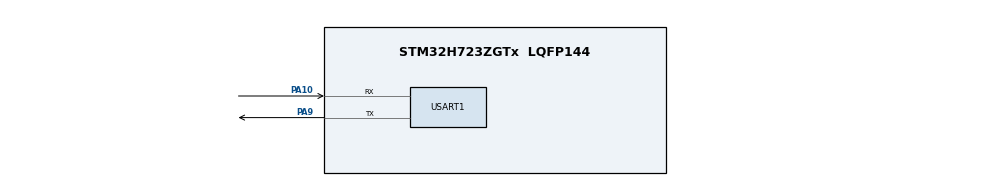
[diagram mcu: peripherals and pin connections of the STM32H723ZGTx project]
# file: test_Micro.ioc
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CORTEX_M7.default_mode_Activation=1
Dma.Request0=USART1_RX
Dma.Request1=USART1_TX
Dma.USART1_RX.0.Direction=DMA_PERIPH_TO_MEMORY
Dma.USART1_RX.0.EventEnable=DISABLE
Dma.USART1_RX.0.FIFOMode=DMA_FIFOMODE_DISABLE
Dma.USART1_RX.0.Instance=DMA1_Stream0
Dma.USART1_RX.0.MemDataAlignment=DMA_MDATAALIGN_BYTE
Dma.USART1_RX.0.MemInc=DMA_MINC_ENABLE
Dma.USART1_RX.0.Mode=DMA_CIRCULAR
Dma.USART1_RX.0.PeriphDataAlignment=DMA_PDATAALIGN_BYTE
Dma.USART1_RX.0.PeriphInc=DMA_PINC_DISABLE
Dma.USART1_RX.0.Polarity=HAL_DMAMUX_REQ_GEN_RISING
Dma.USART1_RX.0.Priority=DMA_PRIORITY_MEDIUM
Dma.USART1_RX.0.RequestNumber=1
Dma.USART1_RX.0.SignalID=NONE
Dma.USART1_RX.0.SyncEnable=DISABLE
Dma.USART1_RX.0.SyncPolarity=HAL_DMAMUX_SYNC_NO_EVENT
Dma.USART1_RX.0.SyncRequestNumber=1
Dma.USART1_RX.0.SyncSignalID=NONE
Dma.USART1_TX.1.Direction=DMA_MEMORY_TO_PERIPH
Dma.USART1_TX.1.EventEnable=DISABLE
Dma.USART1_TX.1.FIFOMode=DMA_FIFOMODE_DISABLE
Dma.USART1_TX.1.Instance=DMA1_Stream1
Dma.USART1_TX.1.MemDataAlignment=DMA_MDATAALIGN_BYTE
Dma.USART1_TX.1.MemInc=DMA_MINC_ENABLE
Dma.USART1_TX.1.Mode=DMA_NORMAL
Dma.USART1_TX.1.PeriphDataAlignment=DMA_PDATAALIGN_BYTE
Dma.USART1_TX.1.PeriphInc=DMA_PINC_DISABLE
Dma.USART1_TX.1.Polarity=HAL_DMAMUX_REQ_GEN_RISING
Dma.USART1_TX.1.Priority=DMA_PRIORITY_MEDIUM
Dma.USART1_TX.1.RequestNumber=1
Dma.USART1_TX.1.SignalID=NONE
Dma.USART1_TX.1.SyncEnable=DISABLE
Dma.USART1_TX.1.SyncPolarity=HAL_DMAMUX_SYNC_NO_EVENT
Dma.USART1_TX.1.SyncRequestNumber=1
Dma.USART1_TX.1.SyncSignalID=NONE
FREERTOS.Tasks01=defaultTask,0,128,StartDefaultTask,Default,NULL,Dynamic,NULL,NULL;debugTask,-3,128,StartdebugTask,Default,NULL,Dynamic,NULL,NULL
Mcu.Family=STM32H7
Mcu.Name=STM32H723ZGTx
Mcu.Package=LQFP144
NVIC.DMA1_Stream0_IRQn=true\:5\:0\:false\:false\:true\:true\:false\:true\:true
NVIC.DMA1_Stream1_IRQn=true\:5\:0\:false\:false\:true\:true\:false\:true\:true
NVIC.PriorityGroup=NVIC_PRIORITYGROUP_4
NVIC.TIM1_UP_IRQn=true\:15\:0\:false\:false\:true\:false\:false\:true\:true
NVIC.TimeBase=TIM1_UP_IRQn
NVIC.TimeBaseIP=TIM1
NVIC.USART1_IRQn=true\:5\:0\:false\:false\:true\:true\:true\:true\:true
PA10.Mode=Asynchronous
PA10.Signal=USART1_RX
PA9.Mode=Asynchronous
PA9.Signal=USART1_TX
PH0-OSC_IN.Mode=HSE-External-Oscillator
PH0-OSC_IN.Signal=RCC_OSC_IN
PH1-OSC_OUT.Mode=HSE-External-Oscillator
PH1-OSC_OUT.Signal=RCC_OSC_OUT
ProjectManager.HeapSize=0x200
ProjectManager.StackSize=0x400
ProjectManager.TargetToolchain=MDK-ARM V5.32
RCC.ADCFreq_Value=129000000
RCC.APB1Freq_Value=137500000
RCC.APB2Freq_Value=137500000
RCC.APB3Freq_Value=137500000
RCC.APB4Freq_Value=137500000
RCC.CortexFreq_Value=550000000
RCC.D1PPRE=RCC_APB3_DIV2
RCC.D2PPRE1=RCC_APB1_DIV2
RCC.D2PPRE2=RCC_APB2_DIV2
RCC.D3PPRE=RCC_APB4_DIV2
RCC.DIVM1=4
RCC.DIVN1=34
RCC.DIVP1=1
RCC.HCLKFreq_Value=275000000
RCC.HPRE=RCC_HCLK_DIV2
RCC.PLL2FRACN=0
RCC.PLL3FRACN=0
RCC.PLLFRACN=3072
RCC.SYSCLKFreq_VALUE=550000000
RCC.SYSCLKSource=RCC_SYSCLKSOURCE_PLLCLK
RCC.USBFreq_Value=275000000
USART1.VirtualMode-Asynchronous=VM_ASYNC
VP_FREERTOS_VS_CMSIS_V1.Mode=CMSIS_V1
VP_MEMORYMAP_VS_MEMORYMAP.Mode=CurAppReg
VP_SYS_VS_tim1.Mode=TIM1
board=custom

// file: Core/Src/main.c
/* USER CODE BEGIN Header */
/**
 ******************************************************************************
 * @file           : main.c
 * @brief          : Main program body
 ******************************************************************************
 * @attention
 *
 * Copyright (c) 2026 STMicroelectronics.
 * All rights reserved.
 *
 * This software is licensed under terms that can be found in the LICENSE file
 * in the root directory of this software component.
 * If no LICENSE file comes with this software, it is provided AS-IS.
 *
 ******************************************************************************
 */
/* USER CODE END Header */
#include "main.h"
#include "cmsis_os.h"
#include "dma.h"
#include "memorymap.h"
#include "usart.h"
#include "gpio.h"

/* USER CODE BEGIN Includes */
#include "rtt_log.h"

#include "SEGGER_RTT.h"
/* USER CODE END Includes */

void SystemClock_Config(void);
static void MPU_Config(void);
void MX_FREERTOS_Init(void);

int main(void)
{

    /* MPU Configuration--------------------------------------------------------*/
    MPU_Config();

    /* MCU Configuration--------------------------------------------------------*/

    /* Reset of all peripherals, Initializes the Flash interface and the Systick. */
    HAL_Init();

    /* Configure the system clock */
    SystemClock_Config();

    /* USER CODE BEGIN SysInit */
    RTT_LogInit();
    // RTT_LogWrite("\r\n[RTT] SEGGER RTT ready.\r\n");

    /* USER CODE END SysInit */

    /* Initialize all configured peripherals */
    MX_GPIO_Init();
    MX_DMA_Init();
    MX_USART1_UART_Init();
    /* USER CODE BEGIN 2 */
    //   comInit();

    // if (USART1_SendString("\r\nUSART1 echo test ready.\r\nSend any data from
    // PC, MCU will echo it back.\r\n") != HAL_OK)
    // {
    //     Error_Handler();
    // }
    // RTT_LogWrite("[APP] USART1 echo test ready.\r\n");
    /* USER CODE END 2 */

    /* Call init function for freertos objects (in cmsis_os2.c) */
    MX_FREERTOS_Init();

    /* Start scheduler */
    osKernelStart();

    /* We should never get here as control is now taken by the scheduler */

    /* Infinite loop */
    while (1)
    {

    }
}

void SystemClock_Config(void)
{
    RCC_OscInitTypeDef RCC_OscInitStruct = {0};
    RCC_ClkInitTypeDef RCC_ClkInitStruct = {0};

    /** Supply configuration update enable
     */
    HAL_PWREx_ConfigSupply(PWR_LDO_SUPPLY);

    /** Configure the main internal regulator output voltage
     */
    __HAL_PWR_VOLTAGESCALING_CONFIG(PWR_REGULATOR_VOLTAGE_SCALE0);

    while (!__HAL_PWR_GET_FLAG(PWR_FLAG_VOSRDY))
    {
    }

    /** Initializes the RCC Oscillators according to the specified parameters
     * in the RCC_OscInitTypeDef structure.
     */
    RCC_OscInitStruct.OscillatorType = RCC_OSCILLATORTYPE_HSI;
    RCC_OscInitStruct.HSIState = RCC_HSI_DIV1;
    RCC_OscInitStruct.HSICalibrationValue = 64;
    RCC_OscInitStruct.PLL.PLLState = RCC_PLL_ON;
    RCC_OscInitStruct.PLL.PLLSource = RCC_PLLSOURCE_HSI;
    RCC_OscInitStruct.PLL.PLLM = 4;
    RCC_OscInitStruct.PLL.PLLN = 34;
    RCC_OscInitStruct.PLL.PLLP = 1;
    RCC_OscInitStruct.PLL.PLLQ = 2;
    RCC_OscInitStruct.PLL.PLLR = 2;
    RCC_OscInitStruct.PLL.PLLRGE = RCC_PLL1VCIRANGE_3;
    RCC_OscInitStruct.PLL.PLLVCOSEL = RCC_PLL1VCOWIDE;
    RCC_OscInitStruct.PLL.PLLFRACN = 3072;
    if (HAL_RCC_OscConfig(&RCC_OscInitStruct) != HAL_OK)
    {
        Error_Handler();
    }

    /** Initializes the CPU, AHB and APB buses clocks
     */
    RCC_ClkInitStruct.ClockType = RCC_CLOCKTYPE_HCLK | RCC_CLOCKTYPE_SYSCLK | RCC_CLOCKTYPE_PCLK1 | RCC_CLOCKTYPE_PCLK2 | RCC_CLOCKTYPE_D3PCLK1 | RCC_CLOCKTYPE_D1PCLK1;
    RCC_ClkInitStruct.SYSCLKSource = RCC_SYSCLKSOURCE_PLLCLK;
    RCC_ClkInitStruct.SYSCLKDivider = RCC_SYSCLK_DIV1;
    RCC_ClkInitStruct.AHBCLKDivider = RCC_HCLK_DIV2;
    RCC_ClkInitStruct.APB3CLKDivider = RCC_APB3_DIV2;
    RCC_ClkInitStruct.APB1CLKDivider = RCC_APB1_DIV2;
    RCC_ClkInitStruct.APB2CLKDivider = RCC_APB2_DIV2;
    RCC_ClkInitStruct.APB4CLKDivider = RCC_APB4_DIV2;

    if (HAL_RCC_ClockConfig(&RCC_ClkInitStruct, FLASH_LATENCY_3) != HAL_OK)
    {
        Error_Handler();
    }
}

/* MPU Configuration */

void MPU_Config(void)
{
    MPU_Region_InitTypeDef MPU_InitStruct = {0};

    /* Disables the MPU */
    HAL_MPU_Disable();

    /** Initializes and configures the Region and the memory to be protected
     */
    MPU_InitStruct.Enable = MPU_REGION_ENABLE;
    MPU_InitStruct.Number = MPU_REGION_NUMBER0;
    MPU_InitStruct.BaseAddress = 0x0;
    MPU_InitStruct.Size = MPU_REGION_SIZE_4GB;
    MPU_InitStruct.SubRegionDisable = 0x87;
    MPU_InitStruct.TypeExtField = MPU_TEX_LEVEL0;
    MPU_InitStruct.AccessPermission = MPU_REGION_NO_ACCESS;
    MPU_InitStruct.DisableExec = MPU_INSTRUCTION_ACCESS_DISABLE;
    MPU_InitStruct.IsShareable = MPU_ACCESS_SHAREABLE;
    MPU_InitStruct.IsCacheable = MPU_ACCESS_NOT_CACHEABLE;
    MPU_InitStruct.IsBufferable = MPU_ACCESS_NOT_BUFFERABLE;

    HAL_MPU_ConfigRegion(&MPU_InitStruct);
    /* Enables the MPU */
    HAL_MPU_Enable(MPU_PRIVILEGED_DEFAULT);
}

void HAL_TIM_PeriodElapsedCallback(TIM_HandleTypeDef *htim)
{
    if (htim->Instance == TIM1)
    {
        HAL_IncTick();
    }
}

void Error_Handler(void)
{
    __disable_irq();
    while (1)
    {
    }
}

#ifdef USE_FULL_ASSERT
/**
 * @brief  Reports the name of the source file and the source line number
 *         where the assert_param error has occurred.
 * @param  file: pointer to the source file name
 * @param  line: assert_param error line source number
 * @retval None
 */
void assert_failed(uint8_t *file, uint32_t line)
{
    /* USER CODE BEGIN 6 */
    /* User can add his own implementation to report the file name and line
       number, ex: printf("Wrong parameters value: file %s on line %d\r\n", file,
       line) */
    /* USER CODE END 6 */
}
#endif /* USE_FULL_ASSERT */

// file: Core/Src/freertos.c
/* USER CODE BEGIN Header */
/**
 ******************************************************************************
 * File Name          : freertos.c
 * Description        : Code for freertos applications
 ******************************************************************************
 * @attention
 *
 * Copyright (c) 2026 STMicroelectronics.
 * All rights reserved.
 *
 * This software is licensed under terms that can be found in the LICENSE file
 * in the root directory of this software component.
 * If no LICENSE file comes with this software, it is provided AS-IS.
 *
 ******************************************************************************
 */
/* USER CODE END Header */

#include "FreeRTOS.h"
#include "task.h"
#include "main.h"
#include "cmsis_os.h"

/* USER CODE BEGIN Includes */
#include "usart.h"
#include "rtt_log.h"
/* USER CODE END Includes */

osThreadId defaultTaskHandle;
osThreadId debugTaskHandle;

void StartDefaultTask(void const *argument);
void StartdebugTask(void const *argument);

void MX_FREERTOS_Init(void); /* (MISRA C 2004 rule 8.1) */

/* GetIdleTaskMemory prototype (linked to static allocation support) */
void vApplicationGetIdleTaskMemory(StaticTask_t **ppxIdleTaskTCBBuffer, StackType_t **ppxIdleTaskStackBuffer, uint32_t *pulIdleTaskStackSize);

/* USER CODE BEGIN GET_IDLE_TASK_MEMORY */
static StaticTask_t xIdleTaskTCBBuffer;
static StackType_t xIdleStack[configMINIMAL_STACK_SIZE];

void vApplicationGetIdleTaskMemory(StaticTask_t **ppxIdleTaskTCBBuffer,
                                   StackType_t **ppxIdleTaskStackBuffer,
                                   uint32_t *pulIdleTaskStackSize)
{
    *ppxIdleTaskTCBBuffer = &xIdleTaskTCBBuffer;
    *ppxIdleTaskStackBuffer = &xIdleStack[0];
    *pulIdleTaskStackSize = configMINIMAL_STACK_SIZE;
    /* place for user code */
}
/* USER CODE END GET_IDLE_TASK_MEMORY */

void MX_FREERTOS_Init(void)
{

    /* Create the thread(s) */
    /* definition and creation of defaultTask */
    osThreadDef(defaultTask, StartDefaultTask, osPriorityNormal, 0, 512);
    defaultTaskHandle = osThreadCreate(osThread(defaultTask), NULL);

    /* definition and creation of debugTask */
    osThreadDef(debugTask, StartdebugTask, osPriorityIdle, 0, 128);
    debugTaskHandle = osThreadCreate(osThread(debugTask), NULL);

}

void StartDefaultTask(void const *argument)
{
    /* USER CODE BEGIN StartDefaultTask */
    static uint32_t s_count = 0;
    uint16_t size = 0;
    uint8_t buf[1024];
    /* Infinite loop */
    for (;;)
    {
        s_count++;

        // if ((s_count % 50000) == 0)
        // {
        /* 串口数据回环测试 */
        size = uart_read(0, buf, sizeof(buf));

        if (size > 0)
        {
            uart_write(0, buf, size);
            // RTT_LogPrintf("uart read size: %u\r\n", size);
            // for (int i = 0; i < size; i++)
            // {
            //     RTT_LogPrintf("%02X ", buf[i]);
            // }
            uart_poll_dma_tx(0);
        }

        /* 将fifo数据拷贝到dma buf，并启动dma传输 */

        // }
        // USART1_Process();
        osDelay(1);
    }
    /* USER CODE END StartDefaultTask */
}

void StartdebugTask(void const *argument)
{
    /* USER CODE BEGIN StartdebugTask */
    /* Infinite loop */
    static uint32_t stack_monitor_tick = 0U;

    for (;;)
    {
        // USART1_CpuMonitorTask();

        uint32_t now = HAL_GetTick();
        if ((now - stack_monitor_tick) >= 1000U)
        {
            stack_monitor_tick = now;
            //   MonitorAllTaskStackUsage();
            //   LogSystemHeapInfo();
        }

        osDelay(1);
    }
    /* USER CODE END StartdebugTask */
}
